# CY8C5868AXI_LP035 register map
File version: 0.1
CY8C58LP
Registers are 32-bit, read-write, no defined reset value unless marked. A register's access mark holds for its fields unless they carry their own. Offsets are from the block's base; lines under a group give offsets from that group; [hi:lo] are bit positions; {n}, {i} and the like mark numbered series; 'fields as' and 'values as' point back to an identical list; <NAME> marks a mode.

## Memory map
0x40004616 ADC_SAR_SAR size 0x158D — SAR ADC
0x40006506 Timer size 0x92
0x4000A000 CAN size 0x28D

## Timer
Base 0x40006506
0x00 Timer_COUNTER 16-bit — UDB.A0 - Current Down Counter Value
0x20 Timer_PERIOD 16-bit — UDB.D0 - Assigned Period
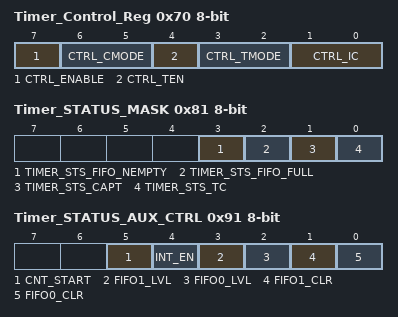
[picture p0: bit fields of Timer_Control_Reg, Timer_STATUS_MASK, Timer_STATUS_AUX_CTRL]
0x70 Timer_Control_Reg 8-bit — UDB Control Register - Assigned Control Register Value
  [7] CTRL_ENABLE — Enable the Timer
  [6:5] CTRL_CMODE — Capture Mode
  [4] CTRL_TEN — Trigger Enable Bit
  [3:2] CTRL_TMODE — Trigger Mode
  [1:0] CTRL_IC — Interrupt Count
0x81 Timer_STATUS_MASK 8-bit — UDB Status bits Interrupt Mask Enable Register
  [3] TIMER_STS_FIFO_NEMPTY ro — FIFO Empty status
  [2] TIMER_STS_FIFO_FULL ro — FIFO Full Status
  [1] TIMER_STS_CAPT ro — Enables the Interrupt on Capture
  [0] TIMER_STS_TC ro — Enables the Interrupt on TC
0x91 Timer_STATUS_AUX_CTRL 8-bit — UDB Auxilliary Control Register
  [5] CNT_START — FIFO0 clear
    0=E_CNT_START0 (Disable counter); 1=E_CNT_START1 (Enable counter)
  [4] INT_EN
    0=E_INT_EN0 (Interrupt disabled); 1=E_INT_EN1 (Interrupt enabled)
  [3] FIFO1_LVL — FIFO level
    0=E_FIFO_LVL_0 (FIFO LVL: input mode: FIFO not full; output mode: FIFO not empty); 1=E_FIFO_LVL_1 (FIFO LVL: input mode: FIFO at least 1/2 empty; output mode: FIFO at least 1/2 full)
  [2] FIFO0_LVL — FIFO level
    values as FIFO1_LVL
  [1] FIFO1_CLR — FIFO1 clear
    0=E_FIFO_CLR_0 (Normal FIFO operation); 1=E_FIFO_CLR_1 (Clear FIFO state)
  [0] FIFO0_CLR — FIFO0 clear
    values as FIFO1_CLR

## CAN
Base 0x4000A000
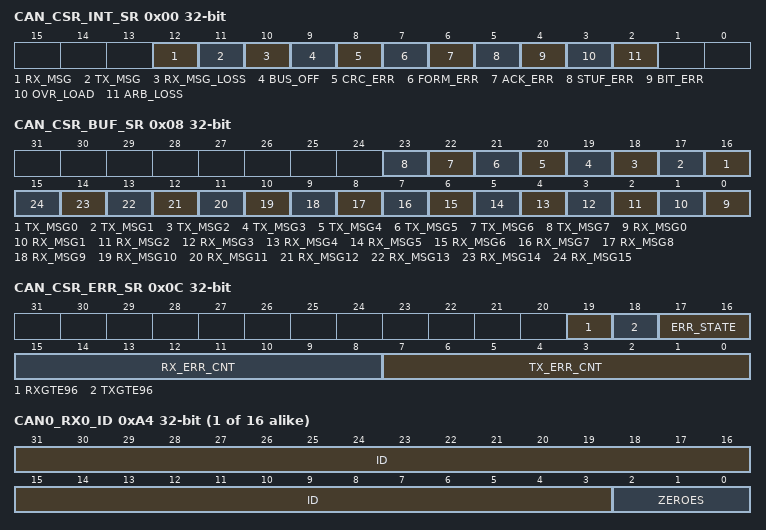
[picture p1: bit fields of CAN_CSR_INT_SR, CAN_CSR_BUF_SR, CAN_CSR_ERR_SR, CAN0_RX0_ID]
0x00 CAN_CSR_INT_SR — The interrupt status register stores internal interrupt events. Once a bit is set it remains set until it is cleared by writing a '1' to it. The interrupt enable register has no effect on the interrupt status register. A pending interrupt occurs when the flag is set to '1'. To acknowledge an interrupt, set the flag to '1'
  [12] RX_MSG — Msg Recieved
  [11] TX_MSG — Tx msg Sent
  [10] RX_MSG_LOSS — Rx msg loss Interrupt
  [9] BUS_OFF — Bus Off State
  [8] CRC_ERR — CRC Error Interrupt
  [7] FORM_ERR — Form Error Interrupt
  [6] ACK_ERR — Ack Error Interrupt
  [5] STUF_ERR — Stuff Error Interrupt
  [4] BIT_ERR — Bit Error Interrupt
  [3] OVR_LOAD — Overload Interrupt
  [2] ARB_LOSS — Arbitration Loss
0x08 CAN_CSR_BUF_SR — These status indicators bundle the respective flags from all RxMessage and TxMessage buffers. Note All flags are read only. To acknowledge a MsgAv flag, the CPU must write to the respective RxMessage buffer
  [n+16] TX_MSG{n} (n=0..7) — Tx req Pending for Tx Msg{n}
  [n] RX_MSG{n} (n=0..15) — Rx Msg{n} Available
0x0C CAN_CSR_ERR_SR — Status indicators are provided to report the CAN controller error state, receive error count, and transmit error count. Special flags report error counter values equal to or in excess of 96 errors are available to indicate heavily disturbed bus situations. The transmitter error counter according to the CAN standard. When it is greater than 255 Decomal, it is fixed at 255 Decimal.
  [19] RXGTE96 — Rx Error Count is greater or equal to 96 Decimal
  [18] TXGTE96 — Tx Error Count is greater or equal to 96 Decimal
  [17:16] ERR_STATE — Error State of CAN node, 00 error active, 01 error passive, 1x bus off
  [15:8] RX_ERR_CNT — Rx error Count. When in bus-off state,this counter is used to count 128 groups of 11 recessive bits
  [7:0] TX_ERR_CNT — Tx error Count
{0x24+0x10*i} CAN0_TX{i}_ID (i=0..7) — CAN Tx Msg Identifier
  [31:3] ID — Tx Msg Indentifier
{0x28+0x10*i} CAN0_TX{i}_DH (i=0..7) — CAN Tx Msg Upper Data Bytes
  [31:0] DATA_HIGH — Upper Data Bytes
{0x2C+0x10*i} CAN0_TX{i}_DL (i=0..7) — CAN Tx Msg Lower Data Bytes
  [31:0] DATA_LOW — Lower Data Bytes
{0xA4+0x20*i} CAN0_RX{i}_ID (i=0..15) — The register contains Rx Msg Identifier
  [31:3] ID — Rx Msg Indentifier
  [2:0] ZEROES — zeros
{0xA8+0x20*i} CAN0_RX{i}_DH (i=0..15) — The register contains the Rx Msg Upper Data Bytes
  [31:0] DATA_HIGH — Upper Data Bytes
{0xAC+0x20*i} CAN0_RX{i}_DL (i=0..15) — The register contains the Rx Msg Lover Data Bytes
  [31:0] DATA_LOW — Lower Data Bytes

## ADC_SAR_SAR — SAR ADC
Base 0x40004616
0x00 SAR_TR0 8-bit — SAR trim register
{0x12F2+i} SAR_CSR{i} 8-bit (i=0..6) — SAR status and control register {i}
0x1512 SAR_SW0 8-bit — SAR Analog Routing Register 0
{0x1512+i} SAR_SW{i} 8-bit (i=2..4) — SAR Analog Routing Register {i}
0x1518 SAR_SW6 8-bit — SAR Analog Routing Register 6
0x1519 SAR_CLK 8-bit — SAR Clock Selection Register
0x158C SAR_WRK 16-bit — SAR working register
